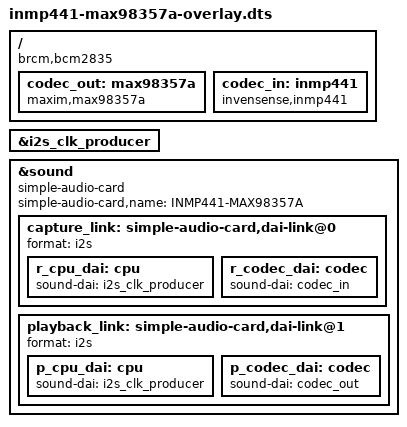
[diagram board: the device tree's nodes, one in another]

/dts-v1/;
/plugin/;

/ {
    compatible = "brcm,bcm2835";

    fragment@0 {
        target-path = "/";
        __overlay__ {
            codec_out: max98357a {
                #sound-dai-cells = <0>;
				compatible = "maxim,max98357a";
                status = "okay";
            };

            codec_in: inmp441 {
                #sound-dai-cells = <0>;
                compatible = "invensense,inmp441";
                status = "okay";
            };
        };
    };

    fragment@1 {
        target = <&i2s_clk_producer>;
        __overlay__ {
            #sound-dai-cells = <0>;
            status = "okay";
        };
    };

    fragment@2 {
        target = <&sound>;
        snd: __overlay__ {
            compatible = "simple-audio-card";
            simple-audio-card,name = "INMP441-MAX98357A";
            status="okay";

            capture_link: simple-audio-card,dai-link@0 {
                format = "i2s";
				
                r_cpu_dai: cpu {
                    sound-dai = <&i2s_clk_producer>;
                };

                r_codec_dai: codec {
                    sound-dai = <&codec_in>;
                };
            };

            playback_link: simple-audio-card,dai-link@1 {
                format = "i2s";

                p_cpu_dai: cpu {
                    sound-dai = <&i2s_clk_producer>;
                };

                p_codec_dai: codec {
                    sound-dai = <&codec_out>;
                };
            };
        };
    };

};
